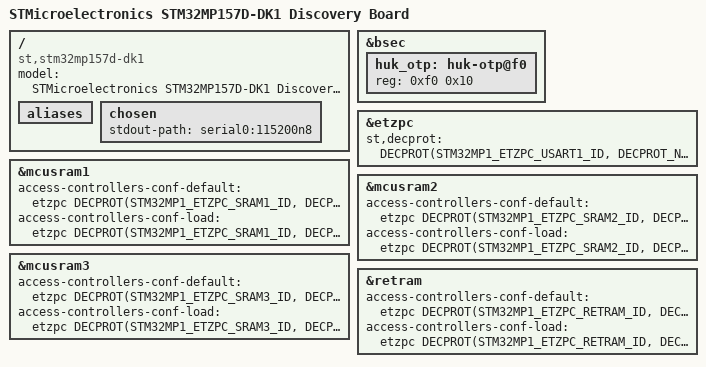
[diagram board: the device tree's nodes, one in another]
// SPDX-License-Identifier: (GPL-2.0-only OR BSD-3-Clause)
/*
 * Copyright (C) STMicroelectronics 2019 - All Rights Reserved
 * Author: Alexandre Torgue <alexandre.torgue@st.com> for STMicroelectronics.
 */

/dts-v1/;

#include "stm32mp157.dtsi"
#include "stm32mp15xd.dtsi"
#include "stm32mp15-pinctrl.dtsi"
#include "stm32mp15xxac-pinctrl.dtsi"
#include "stm32mp15xx-dkx.dtsi"

/ {
	model = "STMicroelectronics STM32MP157D-DK1 Discovery Board";
	compatible = "st,stm32mp157d-dk1", "st,stm32mp157";

	aliases {
	};

	chosen {
		stdout-path = "serial0:115200n8";
	};
};

&bsec {
	huk_otp: huk-otp@f0 {
		reg = <0xf0 0x10>;
	};
};

&etzpc {
	st,decprot = <
		DECPROT(STM32MP1_ETZPC_USART1_ID, DECPROT_NS_RW, DECPROT_UNLOCK)
		DECPROT(STM32MP1_ETZPC_SPI6_ID, DECPROT_NS_RW, DECPROT_UNLOCK)
		DECPROT(STM32MP1_ETZPC_I2C4_ID, DECPROT_NS_RW, DECPROT_UNLOCK)
		DECPROT(STM32MP1_ETZPC_I2C6_ID, DECPROT_NS_RW, DECPROT_UNLOCK)
		DECPROT(STM32MP1_ETZPC_RNG1_ID, DECPROT_S_RW, DECPROT_UNLOCK)
		DECPROT(STM32MP1_ETZPC_HASH1_ID, DECPROT_NS_RW, DECPROT_UNLOCK)
		DECPROT(STM32MP1_ETZPC_DDRCTRL_ID, DECPROT_NS_R_S_W, DECPROT_LOCK)
		DECPROT(STM32MP1_ETZPC_DDRPHYC_ID, DECPROT_NS_R_S_W, DECPROT_LOCK)
		DECPROT(STM32MP1_ETZPC_STGENC_ID, DECPROT_S_RW, DECPROT_LOCK)
		DECPROT(STM32MP1_ETZPC_BKPSRAM_ID, DECPROT_S_RW, DECPROT_LOCK)
		DECPROT(STM32MP1_ETZPC_IWDG1_ID, DECPROT_S_RW, DECPROT_LOCK)
	>;
};

&mcusram1 {
	access-controllers-conf-default = <&etzpc DECPROT(STM32MP1_ETZPC_SRAM1_ID, DECPROT_MCU_ISOLATION, DECPROT_UNLOCK)>;
	access-controllers-conf-load = <&etzpc DECPROT(STM32MP1_ETZPC_SRAM1_ID, DECPROT_S_RW, DECPROT_UNLOCK)>;
};

&mcusram2 {
	access-controllers-conf-default = <&etzpc DECPROT(STM32MP1_ETZPC_SRAM2_ID, DECPROT_MCU_ISOLATION, DECPROT_UNLOCK)>;
	access-controllers-conf-load = <&etzpc DECPROT(STM32MP1_ETZPC_SRAM2_ID, DECPROT_S_RW, DECPROT_UNLOCK)>;
};

&mcusram3 {
	access-controllers-conf-default = <&etzpc DECPROT(STM32MP1_ETZPC_SRAM3_ID, DECPROT_NS_RW, DECPROT_UNLOCK)>;
	access-controllers-conf-load = <&etzpc DECPROT(STM32MP1_ETZPC_SRAM3_ID, DECPROT_S_RW, DECPROT_UNLOCK)>;
};

&retram {
	access-controllers-conf-default = <&etzpc DECPROT(STM32MP1_ETZPC_RETRAM_ID, DECPROT_MCU_ISOLATION, DECPROT_UNLOCK)>;
	access-controllers-conf-load = <&etzpc DECPROT(STM32MP1_ETZPC_RETRAM_ID, DECPROT_S_RW, DECPROT_UNLOCK)>;
};
